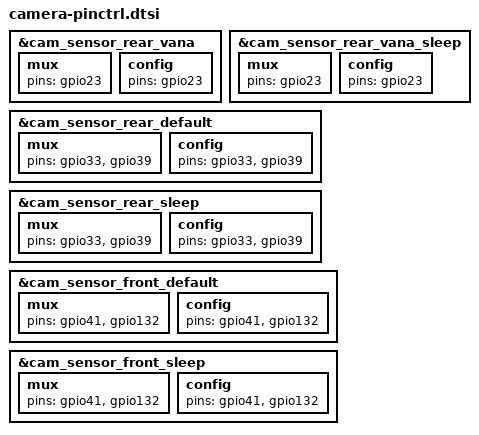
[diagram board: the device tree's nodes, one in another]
/* msm8953-pinctrl.dtsi */
&cam_sensor_rear_vana {
	mux {
		pins = "gpio23";
	};

	config {
		pins = "gpio23";
	};
};
&cam_sensor_rear_vana_sleep {
	mux {
		pins = "gpio23";
	};

	config {
		pins = "gpio23";
	};
};

&cam_sensor_rear_default {
	mux {
		pins = "gpio33", "gpio39";
	};

	config {
		pins = "gpio33", "gpio39";
	};
};

&cam_sensor_rear_sleep {
	mux {
		pins = "gpio33", "gpio39";
	};

	config {
		pins = "gpio33", "gpio39";
	};
};
	
&cam_sensor_front_default {
	mux {
		pins = "gpio41","gpio132";
	};

	config {
		pins = "gpio41","gpio132";
	};
};

&cam_sensor_front_sleep {
	mux {
		pins = "gpio41","gpio132";
	};

	config {
		pins = "gpio41","gpio132";
	};
};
